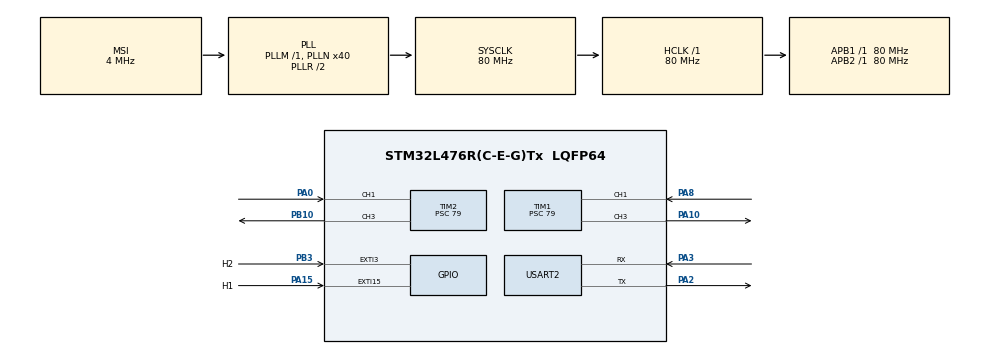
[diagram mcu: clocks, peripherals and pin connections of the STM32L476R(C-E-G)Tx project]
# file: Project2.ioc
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Mcu.Family=STM32L4
Mcu.Name=STM32L476R(C-E-G)Tx
Mcu.Package=LQFP64
NVIC.PriorityGroup=NVIC_PRIORITYGROUP_4
NVIC.USART2_IRQn=true\:0\:0\:false\:false\:true\:true\:true\:true
PA0.Signal=S_TIM2_CH1
PA10.Signal=S_TIM1_CH3
PA15\ (JTDI).GPIO_Label=H1
PA15\ (JTDI).GPIO_PuPd=GPIO_PULLUP
PA15\ (JTDI).Signal=GPXTI15
PA2.Mode=Asynchronous
PA2.Signal=USART2_TX
PA3.Mode=Asynchronous
PA3.Signal=USART2_RX
PA8.Signal=S_TIM1_CH1
PB10.Signal=S_TIM2_CH3
PB3\ (JTDO-TRACESWO).GPIO_Label=H2
PB3\ (JTDO-TRACESWO).GPIO_PuPd=GPIO_PULLUP
PB3\ (JTDO-TRACESWO).Signal=GPXTI3
ProjectManager.HeapSize=0x200
ProjectManager.StackSize=0x400
ProjectManager.TargetToolchain=STM32CubeIDE
RCC.AHBFreq_Value=80000000
RCC.APB1Freq_Value=80000000
RCC.APB1TimFreq_Value=80000000
RCC.APB2Freq_Value=80000000
RCC.APB2TimFreq_Value=80000000
RCC.CortexFreq_Value=80000000
RCC.HCLKFreq_Value=80000000
RCC.HSE_VALUE=8000000
RCC.HSI_VALUE=16000000
RCC.LSE_VALUE=32768
RCC.MSI_VALUE=4000000
RCC.PLLN=40
RCC.SYSCLKFreq_VALUE=80000000
RCC.SYSCLKSource=RCC_SYSCLKSOURCE_PLLCLK
RCC.VCOOutputFreq_Value=160000000
SH.S_TIM1_CH1.0=TIM1_CH1,Input_Capture1_from_TI1
SH.S_TIM1_CH3.0=TIM1_CH3,PWM Generation3 CH3
SH.S_TIM2_CH1.0=TIM2_CH1,Input_Capture1_from_TI1
SH.S_TIM2_CH3.0=TIM2_CH3,PWM Generation3 CH3
TIM1.Channel-Input_Capture1_from_TI1=TIM_CHANNEL_1
TIM1.Channel-PWM\ Generation3\ CH3=TIM_CHANNEL_3
TIM1.Prescaler=79
TIM1.Pulse-PWM\ Generation3\ CH3=10
TIM2.Channel-Input_Capture1_from_TI1=TIM_CHANNEL_1
TIM2.Channel-Input_Capture2_from_TI1_63=TIM_CHANNEL_2
TIM2.Channel-PWM\ Generation3\ CH3=TIM_CHANNEL_3
TIM2.ICPolarity_CH1=TIM_INPUTCHANNELPOLARITY_RISING
TIM2.ICPolarity_CH2=TIM_INPUTCHANNELPOLARITY_FALLING
TIM2.Period=999999
TIM2.Prescaler=79
TIM2.Pulse-PWM\ Generation3\ CH3=10
USART2.VirtualMode-Asynchronous=VM_ASYNC
VP_TIM1_VS_ClockSourceINT.Mode=Internal
VP_TIM2_VS_ClockSourceINT.Mode=Internal
VP_TIM2_VS_indirect_ch1.Mode=Input_Capture2_from_TI1_63
board=custom

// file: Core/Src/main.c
/* USER CODE BEGIN Header */
/**
  ******************************************************************************
  * @file           : main.c
  * @brief          : Main program body
  ******************************************************************************
  * @attention
  *
  * Copyright (c) 2022 STMicroelectronics.
  * All rights reserved.
  *
  * This software is licensed under terms that can be found in the LICENSE file
  * in the root directory of this software component.
  * If no LICENSE file comes with this software, it is provided AS-IS.
  *
  ******************************************************************************
  */
/* USER CODE END Header */
#include "main.h"

/* USER CODE BEGIN Includes */
#include <stdio.h>
/* USER CODE END Includes */

TIM_HandleTypeDef htim1;
TIM_HandleTypeDef htim2;

UART_HandleTypeDef huart2;

void SystemClock_Config(void);
static void MX_GPIO_Init(void);
static void MX_USART2_UART_Init(void);
static void MX_TIM1_Init(void);
static void MX_TIM2_Init(void);

/* USER CODE BEGIN 0 */
int __io_putchar(int ch)
{
  if (ch == '\n') {
    __io_putchar('\r');
  }

  HAL_UART_Transmit(&huart2, (uint8_t*)&ch, 1, HAL_MAX_DELAY);

  return 1;
}
/* USER CODE END 0 */

int main(void)
{

  /* MCU Configuration--------------------------------------------------------*/

  /* Reset of all peripherals, Initializes the Flash interface and the Systick. */
  HAL_Init();

  /* Configure the system clock */
  SystemClock_Config();

  /* Initialize all configured peripherals */
  MX_GPIO_Init();
  MX_USART2_UART_Init();
  MX_TIM1_Init();
  MX_TIM2_Init();

  /* Infinite loop */
  while (1)
  {

  }
}

void SystemClock_Config(void)
{
  RCC_OscInitTypeDef RCC_OscInitStruct = {0};
  RCC_ClkInitTypeDef RCC_ClkInitStruct = {0};

  /** Configure the main internal regulator output voltage
  */
  if (HAL_PWREx_ControlVoltageScaling(PWR_REGULATOR_VOLTAGE_SCALE1) != HAL_OK)
  {
    Error_Handler();
  }
  /** Initializes the RCC Oscillators according to the specified parameters
  * in the RCC_OscInitTypeDef structure.
  */
  RCC_OscInitStruct.OscillatorType = RCC_OSCILLATORTYPE_MSI;
  RCC_OscInitStruct.MSIState = RCC_MSI_ON;
  RCC_OscInitStruct.MSICalibrationValue = 0;
  RCC_OscInitStruct.MSIClockRange = RCC_MSIRANGE_6;
  RCC_OscInitStruct.PLL.PLLState = RCC_PLL_ON;
  RCC_OscInitStruct.PLL.PLLSource = RCC_PLLSOURCE_MSI;
  RCC_OscInitStruct.PLL.PLLM = 1;
  RCC_OscInitStruct.PLL.PLLN = 40;
  RCC_OscInitStruct.PLL.PLLP = RCC_PLLP_DIV7;
  RCC_OscInitStruct.PLL.PLLQ = RCC_PLLQ_DIV2;
  RCC_OscInitStruct.PLL.PLLR = RCC_PLLR_DIV2;
  if (HAL_RCC_OscConfig(&RCC_OscInitStruct) != HAL_OK)
  {
    Error_Handler();
  }
  /** Initializes the CPU, AHB and APB buses clocks
  */
  RCC_ClkInitStruct.ClockType = RCC_CLOCKTYPE_HCLK|RCC_CLOCKTYPE_SYSCLK
                              |RCC_CLOCKTYPE_PCLK1|RCC_CLOCKTYPE_PCLK2;
  RCC_ClkInitStruct.SYSCLKSource = RCC_SYSCLKSOURCE_PLLCLK;
  RCC_ClkInitStruct.AHBCLKDivider = RCC_SYSCLK_DIV1;
  RCC_ClkInitStruct.APB1CLKDivider = RCC_HCLK_DIV1;
  RCC_ClkInitStruct.APB2CLKDivider = RCC_HCLK_DIV1;

  if (HAL_RCC_ClockConfig(&RCC_ClkInitStruct, FLASH_LATENCY_4) != HAL_OK)
  {
    Error_Handler();
  }
}

static void MX_TIM1_Init(void)
{

  TIM_ClockConfigTypeDef sClockSourceConfig = {0};
  TIM_MasterConfigTypeDef sMasterConfig = {0};
  TIM_IC_InitTypeDef sConfigIC = {0};
  TIM_OC_InitTypeDef sConfigOC = {0};
  TIM_BreakDeadTimeConfigTypeDef sBreakDeadTimeConfig = {0};

  htim1.Instance = TIM1;
  htim1.Init.Prescaler = 79;
  htim1.Init.CounterMode = TIM_COUNTERMODE_UP;
  htim1.Init.Period = 65535;
  htim1.Init.ClockDivision = TIM_CLOCKDIVISION_DIV1;
  htim1.Init.RepetitionCounter = 0;
  htim1.Init.AutoReloadPreload = TIM_AUTORELOAD_PRELOAD_DISABLE;
  if (HAL_TIM_Base_Init(&htim1) != HAL_OK)
  {
    Error_Handler();
  }
  sClockSourceConfig.ClockSource = TIM_CLOCKSOURCE_INTERNAL;
  if (HAL_TIM_ConfigClockSource(&htim1, &sClockSourceConfig) != HAL_OK)
  {
    Error_Handler();
  }
  if (HAL_TIM_IC_Init(&htim1) != HAL_OK)
  {
    Error_Handler();
  }
  if (HAL_TIM_PWM_Init(&htim1) != HAL_OK)
  {
    Error_Handler();
  }
  sMasterConfig.MasterOutputTrigger = TIM_TRGO_RESET;
  sMasterConfig.MasterOutputTrigger2 = TIM_TRGO2_RESET;
  sMasterConfig.MasterSlaveMode = TIM_MASTERSLAVEMODE_DISABLE;
  if (HAL_TIMEx_MasterConfigSynchronization(&htim1, &sMasterConfig) != HAL_OK)
  {
    Error_Handler();
  }
  sConfigIC.ICPolarity = TIM_INPUTCHANNELPOLARITY_RISING;
  sConfigIC.ICSelection = TIM_ICSELECTION_DIRECTTI;
  sConfigIC.ICPrescaler = TIM_ICPSC_DIV1;
  sConfigIC.ICFilter = 0;
  if (HAL_TIM_IC_ConfigChannel(&htim1, &sConfigIC, TIM_CHANNEL_1) != HAL_OK)
  {
    Error_Handler();
  }
  sConfigOC.OCMode = TIM_OCMODE_PWM1;
  sConfigOC.Pulse = 10;
  sConfigOC.OCPolarity = TIM_OCPOLARITY_HIGH;
  sConfigOC.OCNPolarity = TIM_OCNPOLARITY_HIGH;
  sConfigOC.OCFastMode = TIM_OCFAST_DISABLE;
  sConfigOC.OCIdleState = TIM_OCIDLESTATE_RESET;
  sConfigOC.OCNIdleState = TIM_OCNIDLESTATE_RESET;
  if (HAL_TIM_PWM_ConfigChannel(&htim1, &sConfigOC, TIM_CHANNEL_3) != HAL_OK)
  {
    Error_Handler();
  }
  sBreakDeadTimeConfig.OffStateRunMode = TIM_OSSR_DISABLE;
  sBreakDeadTimeConfig.OffStateIDLEMode = TIM_OSSI_DISABLE;
  sBreakDeadTimeConfig.LockLevel = TIM_LOCKLEVEL_OFF;
  sBreakDeadTimeConfig.DeadTime = 0;
  sBreakDeadTimeConfig.BreakState = TIM_BREAK_DISABLE;
  sBreakDeadTimeConfig.BreakPolarity = TIM_BREAKPOLARITY_HIGH;
  sBreakDeadTimeConfig.BreakFilter = 0;
  sBreakDeadTimeConfig.Break2State = TIM_BREAK2_DISABLE;
  sBreakDeadTimeConfig.Break2Polarity = TIM_BREAK2POLARITY_HIGH;
  sBreakDeadTimeConfig.Break2Filter = 0;
  sBreakDeadTimeConfig.AutomaticOutput = TIM_AUTOMATICOUTPUT_DISABLE;
  if (HAL_TIMEx_ConfigBreakDeadTime(&htim1, &sBreakDeadTimeConfig) != HAL_OK)
  {
    Error_Handler();
  }
  HAL_TIM_MspPostInit(&htim1);

}

static void MX_TIM2_Init(void)
{

  TIM_ClockConfigTypeDef sClockSourceConfig = {0};
  TIM_MasterConfigTypeDef sMasterConfig = {0};
  TIM_IC_InitTypeDef sConfigIC = {0};
  TIM_OC_InitTypeDef sConfigOC = {0};

  htim2.Instance = TIM2;
  htim2.Init.Prescaler = 79;
  htim2.Init.CounterMode = TIM_COUNTERMODE_UP;
  htim2.Init.Period = 999999;
  htim2.Init.ClockDivision = TIM_CLOCKDIVISION_DIV1;
  htim2.Init.AutoReloadPreload = TIM_AUTORELOAD_PRELOAD_DISABLE;
  if (HAL_TIM_Base_Init(&htim2) != HAL_OK)
  {
    Error_Handler();
  }
  sClockSourceConfig.ClockSource = TIM_CLOCKSOURCE_INTERNAL;
  if (HAL_TIM_ConfigClockSource(&htim2, &sClockSourceConfig) != HAL_OK)
  {
    Error_Handler();
  }
  if (HAL_TIM_IC_Init(&htim2) != HAL_OK)
  {
    Error_Handler();
  }
  if (HAL_TIM_PWM_Init(&htim2) != HAL_OK)
  {
    Error_Handler();
  }
  sMasterConfig.MasterOutputTrigger = TIM_TRGO_RESET;
  sMasterConfig.MasterSlaveMode = TIM_MASTERSLAVEMODE_DISABLE;
  if (HAL_TIMEx_MasterConfigSynchronization(&htim2, &sMasterConfig) != HAL_OK)
  {
    Error_Handler();
  }
  sConfigIC.ICPolarity = TIM_INPUTCHANNELPOLARITY_RISING;
  sConfigIC.ICSelection = TIM_ICSELECTION_DIRECTTI;
  sConfigIC.ICPrescaler = TIM_ICPSC_DIV1;
  sConfigIC.ICFilter = 0;
  if (HAL_TIM_IC_ConfigChannel(&htim2, &sConfigIC, TIM_CHANNEL_1) != HAL_OK)
  {
    Error_Handler();
  }
  sConfigIC.ICPolarity = TIM_INPUTCHANNELPOLARITY_FALLING;
  sConfigIC.ICSelection = TIM_ICSELECTION_INDIRECTTI;
  if (HAL_TIM_IC_ConfigChannel(&htim2, &sConfigIC, TIM_CHANNEL_2) != HAL_OK)
  {
    Error_Handler();
  }
  sConfigOC.OCMode = TIM_OCMODE_PWM1;
  sConfigOC.Pulse = 10;
  sConfigOC.OCPolarity = TIM_OCPOLARITY_HIGH;
  sConfigOC.OCFastMode = TIM_OCFAST_DISABLE;
  if (HAL_TIM_PWM_ConfigChannel(&htim2, &sConfigOC, TIM_CHANNEL_3) != HAL_OK)
  {
    Error_Handler();
  }
  HAL_TIM_MspPostInit(&htim2);

}

static void MX_USART2_UART_Init(void)
{

  huart2.Instance = USART2;
  huart2.Init.BaudRate = 115200;
  huart2.Init.WordLength = UART_WORDLENGTH_8B;
  huart2.Init.StopBits = UART_STOPBITS_1;
  huart2.Init.Parity = UART_PARITY_NONE;
  huart2.Init.Mode = UART_MODE_TX_RX;
  huart2.Init.HwFlowCtl = UART_HWCONTROL_NONE;
  huart2.Init.OverSampling = UART_OVERSAMPLING_16;
  huart2.Init.OneBitSampling = UART_ONE_BIT_SAMPLE_DISABLE;
  huart2.AdvancedInit.AdvFeatureInit = UART_ADVFEATURE_NO_INIT;
  if (HAL_UART_Init(&huart2) != HAL_OK)
  {
    Error_Handler();
  }

}

static void MX_GPIO_Init(void)
{
  GPIO_InitTypeDef GPIO_InitStruct = {0};

  /* GPIO Ports Clock Enable */
  __HAL_RCC_GPIOA_CLK_ENABLE();
  __HAL_RCC_GPIOB_CLK_ENABLE();

  /*Configure GPIO pin : H1_Pin */
  GPIO_InitStruct.Pin = H1_Pin;
  GPIO_InitStruct.Mode = GPIO_MODE_IT_RISING;
  GPIO_InitStruct.Pull = GPIO_PULLUP;
  HAL_GPIO_Init(H1_GPIO_Port, &GPIO_InitStruct);

  /*Configure GPIO pin : H2_Pin */
  GPIO_InitStruct.Pin = H2_Pin;
  GPIO_InitStruct.Mode = GPIO_MODE_IT_RISING;
  GPIO_InitStruct.Pull = GPIO_PULLUP;
  HAL_GPIO_Init(H2_GPIO_Port, &GPIO_InitStruct);

}

void Error_Handler(void)
{
  __disable_irq();
  while (1)
  {
  }
}
